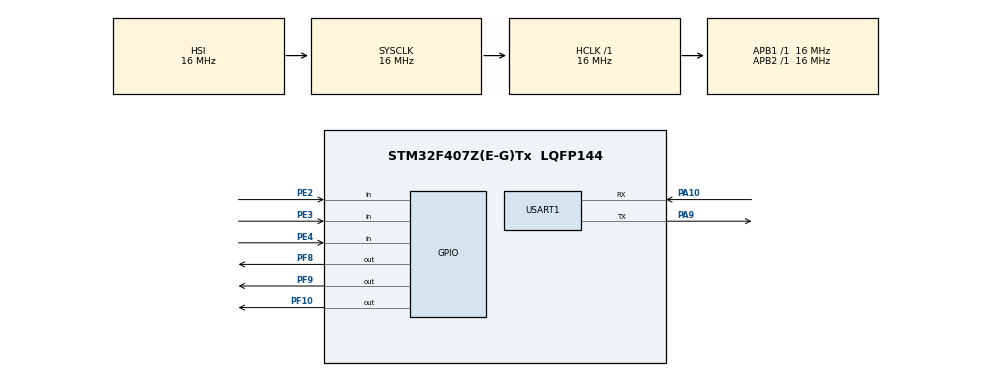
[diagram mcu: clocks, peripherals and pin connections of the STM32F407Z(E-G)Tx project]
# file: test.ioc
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Mcu.Family=STM32F4
RCC.CortexFreq_Value=16000000
PA10.Mode=Asynchronous
PF10.GPIO_PuPd=GPIO_PULLDOWN
ProjectManager.StackSize=0x400
PA13.Signal=SYS_JTMS-SWDIO
PA9.Mode=Asynchronous
ProjectManager.TargetToolchain=Makefile
PA9.Signal=USART1_TX
RCC.LSE_VALUE=32768
RCC.AHBFreq_Value=16000000
PE2.GPIO_PuPd=GPIO_PULLUP
RCC.HSE_VALUE=25000000
PB3.Mode=Trace_Asynchronous_SW
board=custom
RCC.VCOOutputFreq_Value=192000000
RCC.APB2Freq_Value=16000000
PF8.GPIO_ModeDefaultOutputPP=GPIO_MODE_OUTPUT_PP
PF8.GPIO_PuPd=GPIO_PULLDOWN
PA14.Mode=Trace_Asynchronous_SW
PF10.Signal=GPIO_Output
PE3.GPIO_PuPd=GPIO_PULLUP
PE2.Signal=GPIO_Input
PA13.Mode=Trace_Asynchronous_SW
PE4.Signal=GPIO_Input
Mcu.Name=STM32F407Z(E-G)Tx
PE4.GPIO_PuPd=GPIO_PULLUP
PB3.Signal=SYS_JTDO-SWO
RCC.SYSCLKFreq_VALUE=16000000
Mcu.Package=LQFP144
USART1.VirtualMode=VM_ASYNC
PA10.Signal=USART1_RX
PA14.Signal=SYS_JTCK-SWCLK
ProjectManager.HeapSize=0x200
PF8.Signal=GPIO_Output
PF9.Signal=GPIO_Output
RCC.HSI_VALUE=16000000
NVIC.PriorityGroup=NVIC_PRIORITYGROUP_4
PE3.Signal=GPIO_Input
PF9.GPIO_PuPd=GPIO_PULLDOWN
RCC.APB1Freq_Value=16000000

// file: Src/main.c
/* USER CODE BEGIN Header */
/**
  ******************************************************************************
  * @file           : main.c
  * @brief          : Main program body
  ******************************************************************************
  * @attention
  *
  * <h2><center>&copy; Copyright (c) 2020 STMicroelectronics.
  * All rights reserved.</center></h2>
  *
  * This software component is licensed by ST under BSD 3-Clause license,
  * the "License"; You may not use this file except in compliance with the
  * License. You may obtain a copy of the License at:
  *                        opensource.org/licenses/BSD-3-Clause
  *
  ******************************************************************************
  */
/* USER CODE END Header */
#include "main.h"
#include "usart.h"
#include "gpio.h"

void SystemClock_Config(void);

int main(void)
{

  /* MCU Configuration--------------------------------------------------------*/

  /* Reset of all peripherals, Initializes the Flash interface and the Systick. */
  HAL_Init();

  /* Configure the system clock */
  SystemClock_Config();

  /* Initialize all configured peripherals */
  MX_GPIO_Init();
  MX_USART1_UART_Init();
  /* USER CODE BEGIN 2 */
  HAL_GPIO_WritePin(GPIOF, GPIO_PIN_8, GPIO_PIN_RESET);
  HAL_GPIO_WritePin(GPIOF, GPIO_PIN_9, GPIO_PIN_RESET);
  HAL_GPIO_WritePin(GPIOF, GPIO_PIN_10, GPIO_PIN_SET);
  /* USER CODE END 2 */

  /* Infinite loop */
  while (1)
  {

    /* USER CODE BEGIN 3 */

    if (HAL_UART_Transmit(&huart1, (uint8_t *)"11", 3U, 5000U) == HAL_OK)
    {
      HAL_GPIO_WritePin(GPIOF, GPIO_PIN_10, GPIO_PIN_RESET);
    }
    else
    {
      HAL_GPIO_WritePin(GPIOF, GPIO_PIN_10, GPIO_PIN_SET);
    }

    HAL_GPIO_TogglePin(GPIOF,GPIO_PIN_9);
    HAL_Delay(1000);
  }
  /* USER CODE END 3 */
}

void SystemClock_Config(void)
{
  RCC_OscInitTypeDef RCC_OscInitStruct = {0};
  RCC_ClkInitTypeDef RCC_ClkInitStruct = {0};

  /** Configure the main internal regulator output voltage
  */
  __HAL_RCC_PWR_CLK_ENABLE();
  __HAL_PWR_VOLTAGESCALING_CONFIG(PWR_REGULATOR_VOLTAGE_SCALE1);
  /** Initializes the RCC Oscillators according to the specified parameters
  * in the RCC_OscInitTypeDef structure.
  */
  RCC_OscInitStruct.OscillatorType = RCC_OSCILLATORTYPE_HSI;
  RCC_OscInitStruct.HSIState = RCC_HSI_ON;
  RCC_OscInitStruct.HSICalibrationValue = RCC_HSICALIBRATION_DEFAULT;
  RCC_OscInitStruct.PLL.PLLState = RCC_PLL_NONE;
  if (HAL_RCC_OscConfig(&RCC_OscInitStruct) != HAL_OK)
  {
    Error_Handler();
  }
  /** Initializes the CPU, AHB and APB buses clocks
  */
  RCC_ClkInitStruct.ClockType = RCC_CLOCKTYPE_HCLK|RCC_CLOCKTYPE_SYSCLK
                              |RCC_CLOCKTYPE_PCLK1|RCC_CLOCKTYPE_PCLK2;
  RCC_ClkInitStruct.SYSCLKSource = RCC_SYSCLKSOURCE_HSI;
  RCC_ClkInitStruct.AHBCLKDivider = RCC_SYSCLK_DIV1;
  RCC_ClkInitStruct.APB1CLKDivider = RCC_HCLK_DIV1;
  RCC_ClkInitStruct.APB2CLKDivider = RCC_HCLK_DIV1;

  if (HAL_RCC_ClockConfig(&RCC_ClkInitStruct, FLASH_LATENCY_0) != HAL_OK)
  {
    Error_Handler();
  }
}

void Error_Handler(void)
{
  __disable_irq();
  while (1)
  {
  }
}

/************************ (C) COPYRIGHT STMicroelectronics *****END OF FILE****/
